# M051BN_v1 register map
File version: 1.0
Registers are 32-bit, read-write, reset 0x0 unless marked. A register's access mark holds for its fields unless they carry their own. Offsets are from the block's base; [hi:lo] are bit positions; {n}, {i} and the like mark numbered series.

## FMC — FMC Register Map
Base 0x5000C000
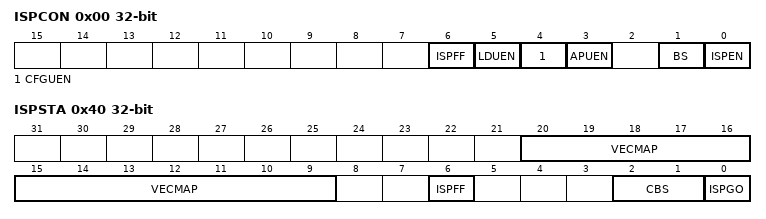
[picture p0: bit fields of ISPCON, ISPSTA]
0x00 ISPCON — ISP Control Register
  [6] ISPFF — ISP Fail Flag (Write Protect). This bit is set by hardware when a triggered ISP meets any of the following conditions: (1) APROM writes to itself if APUEN is set to 0. (2) LDROM writes to itself. (3) Destination address is illegal, such as over an available range. Note: Write 1 to clear this bit to 0.
  [5] LDUEN — LDROM Update Enable Control (Write Protect)
    0=LDROM cannot be updated; 1=LDROM can be updated when the MCU runs in APROM
  [4] CFGUEN — CONFIG Update Enable Control (Write Protect). Writing this bit to 1 enables software to update CONFIG value by ISP register control procedure regardless of program code is running in APROM or LDROM.
    0=ISP update User Configuration Disabled; 1=ISP update User Configuration Enabled
  [3] APUEN — APROM Update Enable Control (Write Protect)
    0=APROM cannot be updated when chip runs in APROM; 1=APROM can be updated when chip runs in APROM
  [1] BS — Boot Select (Write Protect). Set/clear this bit to select next booting from LDROM/APROM, respectively. This bit also functions as chip booting status flag, which can be used to check where chip booted from. This bit is initiated with the inversed value of CBS in CONFIG0 after any reset is happened except CPU reset (RSTS_CPU is 1) or system reset (RSTS_SYS) is happened.
    0=Boot from APROM; 1=Boot from LDROM
  [0] ISPEN — ISP Enable Control (Write Protect). Set this bit to enable ISP function.
    0=ISP function Disabled; 1=ISP function Enabled
0x04 ISPADR — ISP Address Register
  [31:0] ISPADR — ISP Address. The M05xxBN/DN/DE has a maximum 16K x 32-bit (64 KB) of embedded Flash, which supports word program only. ISPADR[1:0] must be kept 00'b for ISP operation.
0x08 ISPDAT — ISP Data Register
  [31:0] ISPDAT — ISP Data. Write data to this register before ISP program operation. Read data from this register after ISP read operation.
0x0C ISPCMD — ISP Command Register
  [5:0] ISPCMD — ISP Command. ISP commands are shown below:
    0=Read; 4=Read Unique ID; 11=Read Company ID (0xDA); 33=Program; 34=Page Erase; 46=Set Vector Page Re-Map
0x10 ISPTRG — ISP Trigger Control Register
  [0] ISPGO — ISP Start Trigger (Write Protect). Write 1 to start ISP operation and this bit will be cleared to 0 by hardware automatically when ISP operation is finished.
    0=ISP operation is finished; 1=ISP operation is progressed
0x14 DFBADR ro reset 0x1F000 — Data Flash Base Address
  [31:0] DFBADR — Data Flash Base Address. This register indicates Data Flash start address. It is a read only register. For 8/16/32/64 Kbytes flash memory device, the Data Flash size is 4 Kbytes and it start address is fixed at 0x0001_F000 by hardware internally.
0x18 FATCON — Flash Access Time Control Register
  [4] LFOM — Low Frequency Optimization Mode Control (Write Protect). When chip operation frequency is lower than 25 MHz, chip can work more efficiently by setting this bit to 1
    0=Low frequency optimization mode Disabled; 1=Low frequency optimization mode Enabled
0x40 ISPSTA — ISP Status Register (M05xxDN/DE Only)
  [20:9] VECMAP ro — Vector Page Mapping Address (Read Only). The current flash address space 0x0000_0000~0x0000_01FF is mapping to address {VECMAP[11:0], 9'h000} ~ {VECMAP[11:0], 9'h1FF}
  [6] ISPFF — ISP Fail Flag (Write Protect). This bit is set by hardware when a triggered ISP meets any of the following conditions: (1) APROM writes to itself (2) LDROM writes to itself (3) CONFIG is erased/programmed if CFGUEN is set to 0 (4) Destination address is illegal, such as over an available range. Write 1 to clear this bit. Note: The function of this bit is the same as ISPCON bit 6
  [2:1] CBS ro — Chip Boot Select (Read Only). This is a mirror of CBS in CONFIG0.
  [0] ISPGO ro — ISP Start Trigger (Read Only). Write 1 to start ISP operation and this bit will be cleared to 0 by hardware automatically when ISP operation is finished. Note: This bit is the same as ISPTRG bit0
    0=ISP operation is finished; 1=ISP operation is progressed
